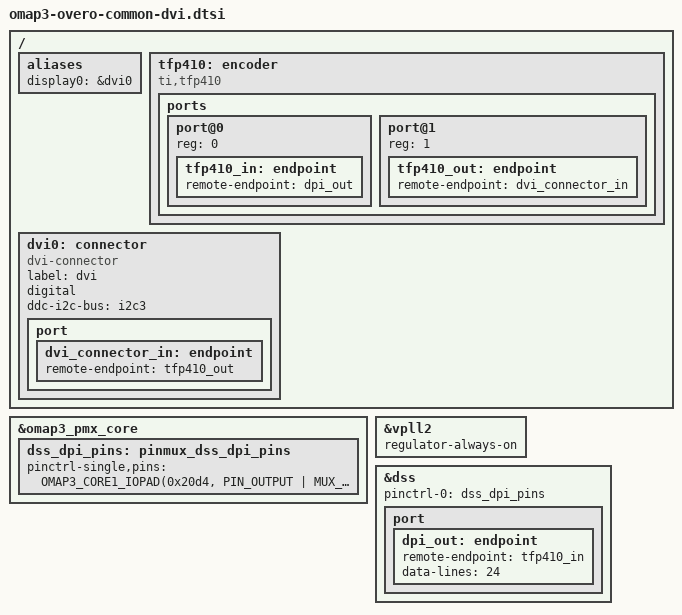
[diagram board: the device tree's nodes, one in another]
// SPDX-License-Identifier: GPL-2.0-only
/*
 * Copyright (C) 2014 Florian Vaussard, EPFL Mobots group
 */

/*
 * DVI output for some Gumstix Overo boards (Tobi and Summit)
 */

&omap3_pmx_core {
	dss_dpi_pins: pinmux_dss_dpi_pins {
		pinctrl-single,pins = <
			OMAP3_CORE1_IOPAD(0x20d4, PIN_OUTPUT | MUX_MODE0)	/* dss_pclk.dss_pclk */
			OMAP3_CORE1_IOPAD(0x20d6, PIN_OUTPUT | MUX_MODE0)	/* dss_hsync.dss_hsync */
			OMAP3_CORE1_IOPAD(0x20d8, PIN_OUTPUT | MUX_MODE0)	/* dss_vsync.dss_vsync */
			OMAP3_CORE1_IOPAD(0x20da, PIN_OUTPUT | MUX_MODE0)	/* dss_acbias.dss_acbias */
			OMAP3_CORE1_IOPAD(0x20dc, PIN_OUTPUT | MUX_MODE0)	/* dss_data0.dss_data0 */
			OMAP3_CORE1_IOPAD(0x20de, PIN_OUTPUT | MUX_MODE0)	/* dss_data1.dss_data1 */
			OMAP3_CORE1_IOPAD(0x20e0, PIN_OUTPUT | MUX_MODE0)	/* dss_data2.dss_data2 */
			OMAP3_CORE1_IOPAD(0x20e2, PIN_OUTPUT | MUX_MODE0)	/* dss_data3.dss_data3 */
			OMAP3_CORE1_IOPAD(0x20e4, PIN_OUTPUT | MUX_MODE0)	/* dss_data4.dss_data4 */
			OMAP3_CORE1_IOPAD(0x20e6, PIN_OUTPUT | MUX_MODE0)	/* dss_data5.dss_data5 */
			OMAP3_CORE1_IOPAD(0x20e8, PIN_OUTPUT | MUX_MODE0)	/* dss_data6.dss_data6 */
			OMAP3_CORE1_IOPAD(0x20ea, PIN_OUTPUT | MUX_MODE0)	/* dss_data7.dss_data7 */
			OMAP3_CORE1_IOPAD(0x20ec, PIN_OUTPUT | MUX_MODE0)	/* dss_data8.dss_data8 */
			OMAP3_CORE1_IOPAD(0x20ee, PIN_OUTPUT | MUX_MODE0)	/* dss_data9.dss_data9 */
			OMAP3_CORE1_IOPAD(0x20f0, PIN_OUTPUT | MUX_MODE0)	/* dss_data10.dss_data10 */
			OMAP3_CORE1_IOPAD(0x20f2, PIN_OUTPUT | MUX_MODE0)	/* dss_data11.dss_data11 */
			OMAP3_CORE1_IOPAD(0x20f4, PIN_OUTPUT | MUX_MODE0)	/* dss_data12.dss_data12 */
			OMAP3_CORE1_IOPAD(0x20f6, PIN_OUTPUT | MUX_MODE0)	/* dss_data13.dss_data13 */
			OMAP3_CORE1_IOPAD(0x20f8, PIN_OUTPUT | MUX_MODE0)	/* dss_data14.dss_data14 */
			OMAP3_CORE1_IOPAD(0x20fa, PIN_OUTPUT | MUX_MODE0)	/* dss_data15.dss_data15 */
			OMAP3_CORE1_IOPAD(0x20fc, PIN_OUTPUT | MUX_MODE0)	/* dss_data16.dss_data16 */
			OMAP3_CORE1_IOPAD(0x20fe, PIN_OUTPUT | MUX_MODE0)	/* dss_data17.dss_data17 */
			OMAP3_CORE1_IOPAD(0x2100, PIN_OUTPUT | MUX_MODE0)	/* dss_data18.dss_data18 */
			OMAP3_CORE1_IOPAD(0x2102, PIN_OUTPUT | MUX_MODE0)	/* dss_data19.dss_data19 */
			OMAP3_CORE1_IOPAD(0x2104, PIN_OUTPUT | MUX_MODE0)	/* dss_data20.dss_data20 */
			OMAP3_CORE1_IOPAD(0x2106, PIN_OUTPUT | MUX_MODE0)	/* dss_data21.dss_data21 */
			OMAP3_CORE1_IOPAD(0x2108, PIN_OUTPUT | MUX_MODE0)	/* dss_data22.dss_data22 */
			OMAP3_CORE1_IOPAD(0x210a, PIN_OUTPUT | MUX_MODE0)	/* dss_data23.dss_data23 */
		>;
	};
};

/* Needed to power the DPI pins */
&vpll2 {
	regulator-always-on;
};

&dss {
	status = "ok";

	pinctrl-names = "default";
	pinctrl-0 = <&dss_dpi_pins>;

	port {
		dpi_out: endpoint {
			remote-endpoint = <&tfp410_in>;
			data-lines = <24>;
		};
	};
};

/ {
	aliases {
		display0 = &dvi0;
	};

	tfp410: encoder {
		compatible = "ti,tfp410";

		ports {
			#address-cells = <1>;
			#size-cells = <0>;

			port@0 {
				reg = <0>;

				tfp410_in: endpoint {
					remote-endpoint = <&dpi_out>;
				};
			};

			port@1 {
				reg = <1>;

				tfp410_out: endpoint {
					remote-endpoint = <&dvi_connector_in>;
				};
			};
		};
	};

	dvi0: connector {
		compatible = "dvi-connector";
		label = "dvi";

		digital;
		ddc-i2c-bus = <&i2c3>;

		port {
			dvi_connector_in: endpoint {
				remote-endpoint = <&tfp410_out>;
			};
		};
	};
};

